# RS1xxxx register map
Vendor: Silicon Lab Inc.; Series: ARMCM4; File version: 1.2
CPU: CM4 r1p0, little endian, MPU, FPU, 6 interrupt priority bits
Registers are 32-bit, read-write, reset 0x0 unless marked. A register's access mark holds for its fields unless they carry their own. Offsets are from the block's base; [hi:lo] are bit positions; lines under a group give offsets from that group; {n}, {i} and the like mark numbered series; 'fields as' and 'values as' point back to an identical list.

## AUX_ADC_DAC_COMP — The ADC-DAC Controller works on a ADC with a resolution of 12bits at 5Mega sample per second when ADC reference Voltage is greater than 2.8v or 5Mega sample per second when ADC reference Voltage is less than 2.8v.
Base 0x24043800
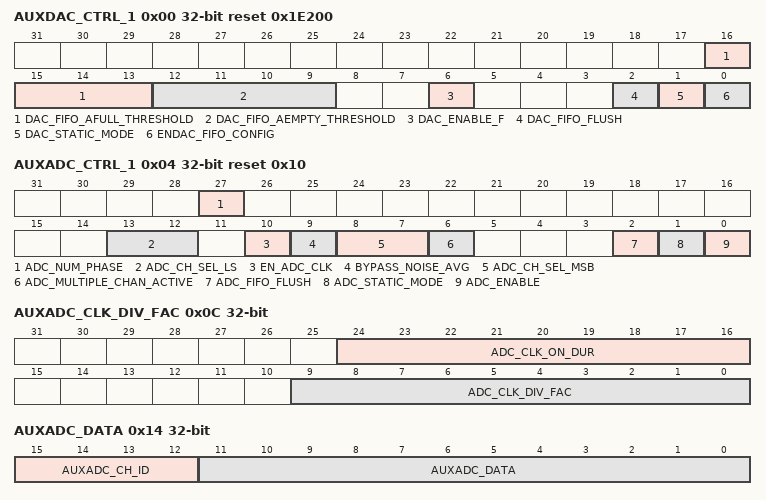
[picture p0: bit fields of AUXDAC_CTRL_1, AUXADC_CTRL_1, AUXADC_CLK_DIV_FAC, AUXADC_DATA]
0x00 AUXDAC_CTRL_1 reset 0x1E200 — Control register1 for DAC
  [16:13] DAC_FIFO_AFULL_THRESHOLD — It is recommended to write these bits to 0
  [12:9] DAC_FIFO_AEMPTY_THRESHOLD — It is recommended to write these bits to 0
  [6] DAC_ENABLE_F — This bit is used to enable AUX DAC controller ,valid only when DAC enable is happpen
    1=Enable DAC Controller; 0=Disable DAC Controller
  [2] DAC_FIFO_FLUSH — This bit is used to flush the DAC FIFO.
    1=Enable (Flush dac FIFO); 0=Disable (Do not flush)
  [1] DAC_STATIC_MODE — This bit is used to select non-FIFO mode in DAC.
    1=Enable (Static mode is enabled. Data written to the DAC_DATA_REG will not be written to the FIFO. It will be played on DAC directly. Only single sample can be held at a time); 0=Disable (FIFO mode enabled. Data written to the DAC_DATA_REG is written to the FIFO in this mode. In either of these modes, data will be driven to the DAC only when dac_enable is set.)
  [0] ENDAC_FIFO_CONFIG — This bit activates the DAC path in Aux ADC-DAC controller. Data samples will be played on DAC only when this bit is set.
    1=Enable fifo configuration of DAC; 0=Disable fifo configuration of DAC
0x04 AUXADC_CTRL_1 reset 0x10 — Control register1 for ADC
  [27] ADC_NUM_PHASE — ADC number of phase
  [13:12] ADC_CH_SEL_LS — Aux ADC channel number from which the data has to be sampled This is valid only when adc multiple channel active is zero. When channel number is greater than three, upper bits should also be programmed ADC CHANNEL SELECT MS to bits in this register
    {v}=CHANNEL_{v} (v=0..3)
  [10] EN_ADC_CLK — Enable AUX ADC Divider output clock
  [9] BYPASS_NOISE_AVG — ADC in Bypass noise avg mode.
  [8:7] ADC_CH_SEL_MSB — Upper 2-bits of adc channel select.When the channel number is greater than 3, these have to be used.It is recommended to write these bits to 0
  [6] ADC_MULTIPLE_CHAN_ACTIVE — This bit is used to control the auxadc sel signal going to the Aux ADC.
    1=Enable (Data will be sampled from four ADC channels in sequential order and written to the receive FIFO in the same order.); 0=Disable (Data will be sampled from the programmed ADC channel)
  [2] ADC_FIFO_FLUSH — This bit is used to flush the ADC FIFO
    1=Enable (Flush ADC FIFO); 0=Disable (Do not flush)
  [1] ADC_STATIC_MODE — This bit is used to select non-FIFO mode in ADC.
    1=Enable (Static mode enable here data directly to register not in FIFO); 0=Disable (FIFO mode enabled here data directly to FIFO.)
  [0] ADC_ENABLE — This bits activates the ADC path in Aux ADC-DAC controller.
    1=Enable ADC; 0=Disable ADC
0x08 AUXDAC_CLK_DIV_FAC — DAC clock division register
  [9:0] DAC_CLK_DIV_FAC — These bits control the DAC clock division factor
0x0C AUXADC_CLK_DIV_FAC — ADC clock division register
  [24:16] ADC_CLK_ON_DUR — These bits control the On-Duration of the ADC clock
  [9:0] ADC_CLK_DIV_FAC — These bits control the Total-Duration of the ADC clock
0x10 AUXDAC_DATA — Writing to this register will fill DAC FIFO for streaming Data to DAC
  [9:0] AUXDAC_DATA
0x14 AUXADC_DATA — AUXADC Data Read through Register.
  [15:12] AUXADC_CH_ID ro — AUXADC Channel ID
  [11:0] AUXADC_DATA ro — AUXADC Data Read through Register
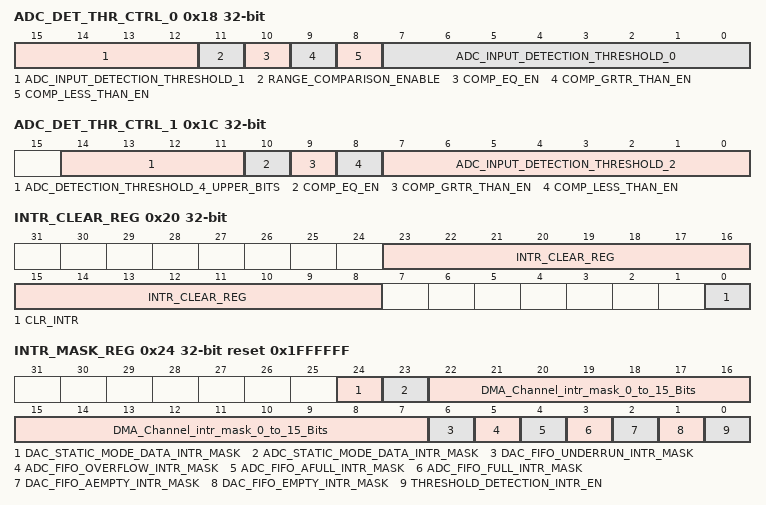
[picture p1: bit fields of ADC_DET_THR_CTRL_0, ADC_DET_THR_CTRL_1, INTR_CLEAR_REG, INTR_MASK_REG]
0x18 ADC_DET_THR_CTRL_0 — ADC detection threshold control 0
  [15:12] ADC_INPUT_DETECTION_THRESHOLD_1 — Carries upper four bits of ADC detection threshold
  [11] RANGE_COMPARISON_ENABLE — When set, Aux ADC-DAC controller raises an interrupt to processor when the Aux ADC output falls within the range specified in AUX ADC Detection threshold0 and AUX ADC Detection threshold1
    1=Enable range comparison; 0=Disable range comparison
  [10] COMP_EQ_EN — When set, Aux ADC-DAC controller raises an interrupt to processor when the Aux ADC output is equal to the programmed Aux ADC detection threshold
    1=Enable compare equal bit; 0=Disable compare equal bit
  [9] COMP_GRTR_THAN_EN — When set, Aux ADC-DAC controller raises an interrupt to processor when the Aux ADC output is greater than the programmed Aux ADC detection threshold..
    1=Enable grater than mode; 0=Disable grater than mode
  [8] COMP_LESS_THAN_EN — When set, Aux ADC-DAC controller raises an interrupt to processor when the Aux ADC output falls below the programmed Aux ADC detection threshold.
    1=Enable less than mode; 0=Disable less than mode
  [7:0] ADC_INPUT_DETECTION_THRESHOLD_0 — The value against which the ADC output has to be compared is to be programmed in this register
0x1C ADC_DET_THR_CTRL_1 — ADC detection threshold control 1
  [14:11] ADC_DETECTION_THRESHOLD_4_UPPER_BITS — Upper 4 bits of ADC detection threshold 2 for ADC
  [10] COMP_EQ_EN — When set, Aux ADC-DAC controller raises an interrupt to TA when the Aux ADC output is equal to the programmed Aux ADC detection threshold.
    1=Enable compare equal bit; 0=Disable compare equal bit
  [9] COMP_GRTR_THAN_EN — When set, Aux ADC-DAC controller raises an interrupt to TA when the Aux ADC output is greater than the programmed Aux ADC detection threshold.
    1=Enable grater than mode; 0=Disable grater than mode
  [8] COMP_LESS_THAN_EN — When set, Aux ADC-DAC controller raises an interrupt to TA when the Aux ADC output falls below the programmed Aux ADC detection threshold.
    1=Enable less than mode; 0=Disable less than mode
  [7:0] ADC_INPUT_DETECTION_THRESHOLD_2 — The value against which the ADC output has to be compared is to be programmed in this register.
0x20 INTR_CLEAR_REG — ADC detection threshold control 1
  [23:8] INTR_CLEAR_REG — If enabled, corresponding first_mem_switch_intr bits will be cleared.
  [0] CLR_INTR — This bit is used to clear threshold detection interrupt
    1=CLEAR_INTERRUPT (Clear the interrupt); 0=NO_EFFECT (Disable compare equal bit)
0x24 INTR_MASK_REG reset 0x1FFFFFF — Mask interrupt register
  [24] DAC_STATIC_MODE_DATA_INTR_MASK — When Cleared, dac static_mode_data_intr will be unmasked
  [23] ADC_STATIC_MODE_DATA_INTR_MASK — When Cleared, adc static_mode_data_intr will be unmasked
  [22:7] DMA_Channel_intr_mask_0_to_15_Bits — When Cleared, first_mem_switch_intr will be unmasked
  [6] DAC_FIFO_UNDERRUN_INTR_MASK — When Cleared, dac FIFO underrun interrupt will be unmasked
    1=MASK_INTERRUPT (When bit is set mask the interrupt); 0=UNMASK_EFFECT (When bit is clear unmask the interrupt)
  [5] ADC_FIFO_OVERFLOW_INTR_MASK — When Cleared, dac FIFO underrun interrupt will be unmasked
    values as DAC_FIFO_UNDERRUN_INTR_MASK
  [4] ADC_FIFO_AFULL_INTR_MASK — When Cleared, adc FIFO afull interrupt will be unmasked
    values as DAC_FIFO_UNDERRUN_INTR_MASK
  [3] ADC_FIFO_FULL_INTR_MASK — When Cleared, adc FIFO full interrupt will be unmasked
    values as DAC_FIFO_UNDERRUN_INTR_MASK
  [2] DAC_FIFO_AEMPTY_INTR_MASK — When Cleared, adc FIFO full interrupt will be unmasked
    values as DAC_FIFO_UNDERRUN_INTR_MASK
  [1] DAC_FIFO_EMPTY_INTR_MASK — When Cleared, dac_FIFO_empty interrupt will be unmasked
    values as DAC_FIFO_UNDERRUN_INTR_MASK
  [0] THRESHOLD_DETECTION_INTR_EN — When Cleared, threshold detection interrupt will be unmasked
    values as DAC_FIFO_UNDERRUN_INTR_MASK
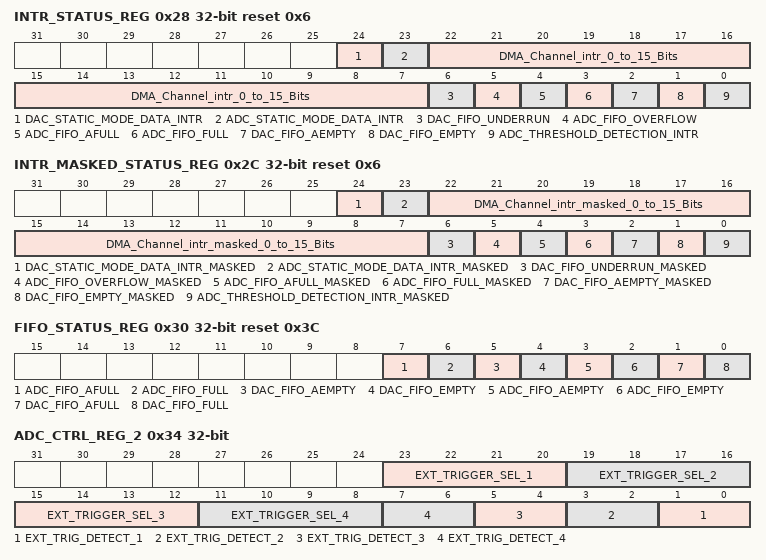
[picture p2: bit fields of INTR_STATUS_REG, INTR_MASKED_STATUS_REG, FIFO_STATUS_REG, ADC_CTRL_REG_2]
0x28 INTR_STATUS_REG ro reset 0x6 — Status interrupt register
  [24] DAC_STATIC_MODE_DATA_INTR — Set when a proper data packet is ready to read in static mode for DAC
  [23] ADC_STATIC_MODE_DATA_INTR — Set when a proper data packet is ready to read in static mode for ADC
  [22:7] DMA_Channel_intr_0_to_15_Bits — Interrupt indicating the first memory has been filled and the DMA write is being shifted to second memory chunk for ping-pong operation
  [6] DAC_FIFO_UNDERRUN — Set when a read is done on DAC FIFO when the FIFO is empty
  [5] ADC_FIFO_OVERFLOW — Set when a write attempt is made to ADC FIFO when the FIFO is already full
  [4] ADC_FIFO_AFULL — Set when ADC FIFO occupancy less than or equal to ADC FIFO threshold
  [3] ADC_FIFO_FULL — Set when ADC FIFO is full,This bit gets cleared when data is read from the FIFO
  [2] DAC_FIFO_AEMPTY — Set when the FIFO occupancy grater than or equal to DAC FIFO threshold.
  [1] DAC_FIFO_EMPTY — Set when DAC FIFO is empty. This bit gets cleared when the DAC FIFO at least a single sample is available in DAC FIFO
  [0] ADC_THRESHOLD_DETECTION_INTR — This bit is set when ADC threshold matches with the programmed conditions This will be be cleared as soon as this interrupt is acknowledged by processor
0x2C INTR_MASKED_STATUS_REG ro reset 0x6 — Interrupt masked status register
  [24] DAC_STATIC_MODE_DATA_INTR_MASKED — Masked Interrupt. Set when a proper data packet is ready to read in static mode for DAC
  [23] ADC_STATIC_MODE_DATA_INTR_MASKED — Masked Interrupt. Set when a proper data packet is ready to read in static mode for ADC
  [22:7] DMA_Channel_intr_masked_0_to_15_Bits — Masked Interrupt status indicating the first memory has been filled and the DMA write is being shifted to second memory chunk for ping-pong operation
  [6] DAC_FIFO_UNDERRUN_MASKED — Masked Interrupt. Set when a read is done on DAC FIFO when the FIFO is empty.
  [5] ADC_FIFO_OVERFLOW_MASKED — Masked Interrupt. Set when a write attempt is made to ADC FIFO when the FIFO is already full.
  [4] ADC_FIFO_AFULL_MASKED — Masked Interrupt. Set when ADC FIFO occupancy greater than ADC FIFO threshold
  [3] ADC_FIFO_FULL_MASKED — Masked Interrupt. Set when ADC FIFO is full.
  [2] DAC_FIFO_AEMPTY_MASKED — Masked Interrupt. Set when the FIFO occupancy less than equal to DAC FIFO threshold.
  [1] DAC_FIFO_EMPTY_MASKED — Masked Interrupt.Set when DAC FIFO is empty
  [0] ADC_THRESHOLD_DETECTION_INTR_MASKED — Masked Interrupt. This bit is set when ADC threshold matches with the programmed conditions
0x30 FIFO_STATUS_REG ro reset 0x3C — Interrupt masked status register
  [7] ADC_FIFO_AFULL — Set when ADC FIFO occupancy greater than ADC FIFO threshold.
  [6] ADC_FIFO_FULL — Set when ADC FIFO is full. This bit gets cleared when data is read from the FIFO.
  [5] DAC_FIFO_AEMPTY — Set when the FIFO occupancy less than DAC FIFO threshold
  [4] DAC_FIFO_EMPTY — Set when FIFO is empty. This bit gets cleared when the DAC FIFO is not empty.
  [3] ADC_FIFO_AEMPTY — Set when the FIFO occupancy less than ADC FIFO threshold
  [2] ADC_FIFO_EMPTY — Set when FIFO is empty. This bit gets cleared when the ADC FIFO is not empty.
  [1] DAC_FIFO_AFULL — Set when DAC FIFO occupancy greater than FIFO threshold
  [0] DAC_FIFO_FULL — Set when DAC FIFO is full. In word mode, FIFO will be shown as full unless there is space for 16-bits.
0x34 ADC_CTRL_REG_2 — ADC Control register2
  [23:20] EXT_TRIGGER_SEL_1 — 4-bit Channel ID corresponding to external trigger 1.
  [19:16] EXT_TRIGGER_SEL_2 — Enable bit corresponding to channel id selected for trigger 2.
  [15:12] EXT_TRIGGER_SEL_3 — 4-bit Channel ID corresponding to external trigger 3.
  [11:8] EXT_TRIGGER_SEL_4 — 4-bit Channel ID corresponding to external trigger 4.
  [2n-1:2n-2] EXT_TRIG_DETECT_{n} (n=1..4) — Condition to detect event on external trigger {n} 00: None (trigger disabled) 01: Positive edge 10: Negative edge 11: Positive or negative edge.
{0x38+0x10*i} ADC_CHn_BIT_MAP_CONFIG[{i}] (i=0..15) group — ADC Channel bit map configuration registers(0-15)
  {0x0+4j} ADC_CH_n__BIT_MAP_CONFIG_{j} (j=0..2) — This is configuration register{j} to explain the bit map for ADC channels
    [31:0] CHANNEL__n__BITMAP — ADC Channels bit map
  0x0C ADC_CH_n__BIT_MAP_CONFIG_3 — This is configuration register3 to explain the bit map for ADC channels
    [4:0] CHANNEL__n__BITMAP — ADC Channels bit map
{0x138+4i} ADC_CHn_OFFSET[{i}] (i=0..15) group — Initial offset value with respect to AUX_ADC clock after which Channel(0-15)should be sampled
  0x00 ADC_CH_n1__OFFSET — This Register specifies initial offset value with respect to AUX_ADC clock after which should sample channel.
    [15:0] CH_n__OFFSET — This Register field specifies initial offset value with respect to AUX_ADC clock after which Channel(0-16)should be sampled.
{0x178+4i} ADC_CHn_FREQ[{i}] (i=0..15) group — This register specifies Sampling frequency rate at which AUX ADC Date is sampled for Channel(1 to 16 )
  0x00 ADC_CH_n1__FREQ — This register specifies Sampling frequency rate at which AUX ADC Date is sampled for Channel
    [15:0] CH_n__FREQ_VALUE — This register specifies Sampling frequency rate at which AUX ADC Date is sampled for Channel all respective channel (1-16)
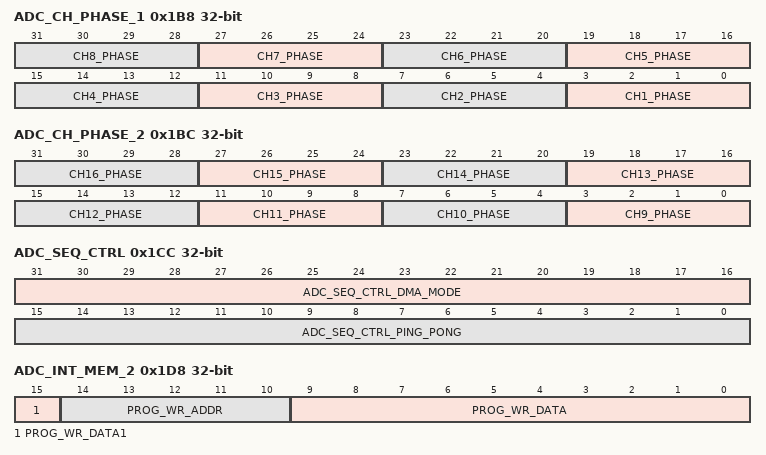
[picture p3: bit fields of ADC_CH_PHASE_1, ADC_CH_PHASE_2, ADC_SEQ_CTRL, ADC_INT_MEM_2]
0x1B8 ADC_CH_PHASE_1 — ADC Channel Phase 1
  [4n-1:4n-4] CH{n}_PHASE (n=1..8) — Phase corresponding to channel-{n}
0x1BC ADC_CH_PHASE_2 — ADC Channel Phase 2
  [4n-33:4n-36] CH{n}_PHASE (n=9..16) — Phase corresponding to channel-{n}
0x1C4 ADC_SINGLE_CH_CTRL_1 — ADC SINGLE Channel Configuration
  [31:0] ADC_CH_INDEX_SINGLE_CHAN_1 — [31:0]out of total 48 bits of bit map for single channel mode of a particular channel.
0x1C8 ADC_SINGLE_CH_CTRL_2 — ADC SINGLE Channel Configuration
  [15:0] ADC_CH_INDEX_SINGLE_CHAN_2 — [47:32] out of total 48 bits of bit map for single channel mode of a particular channel.
0x1CC ADC_SEQ_CTRL — This register explain configuration parameter for AUXADC
  [31:16] ADC_SEQ_CTRL_DMA_MODE — To enable/disable per channel ping-pong operation (One-hot coding).
  [15:0] ADC_SEQ_CTRL_PING_PONG — To enable/disable per channel DAM mode (One-hot coding)
0x1D0 VAD_BBP_ID — This register explain VDD BBP ID
  [31:16] DISCONNET_MODE — Per channel discontinuous mode enable signal. When discontinuous mode is enabled,data is sampled only once from that channel and the enable bit is reset to 0.
0x1D4 ADC_INT_MEM_1 — This register explain start address of first/second buffer corresponding to the channel location ADC INT MEM 2
  [31:0] PROG_WR_DATA — These 32-bits specifies the start address of first/second buffer corresponding to the channel location ADC INT MEM
0x1D8 ADC_INT_MEM_2 — This register explain ADC INT MEM2.
  [15] PROG_WR_DATA1 — Valid bit for first/second buffers corresponding to ADC INT MEM2
  [14:10] PROG_WR_ADDR — These bits correspond to the address of the internal memory basing on the channel number, whose information we want to program
  [9:0] PROG_WR_DATA — These 10-bits specify the buffer length of first/second buffer corresponding to the channel location ADC INT MEM2
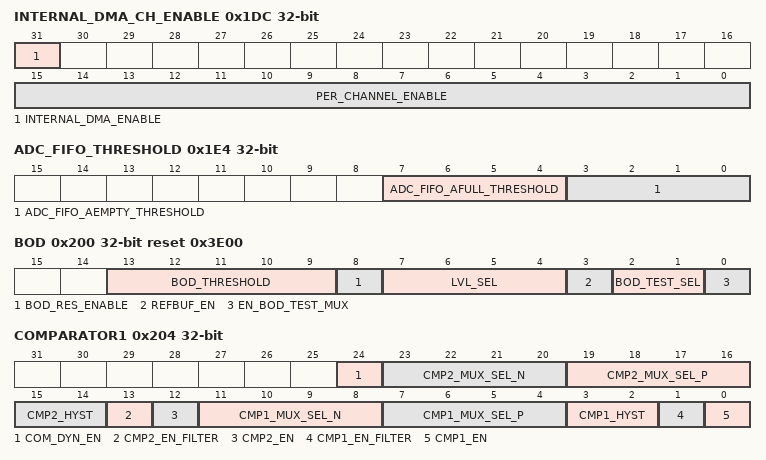
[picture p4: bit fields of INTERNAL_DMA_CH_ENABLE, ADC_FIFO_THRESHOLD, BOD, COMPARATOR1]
0x1DC INTERNAL_DMA_CH_ENABLE — This register is internal channel enable
  [31] INTERNAL_DMA_ENABLE — When Set, Internal DMA will be used for reading ADC samples from ADC FIFO and writing them to ULP SRAM Memories.
  [15:0] PER_CHANNEL_ENABLE — Enable bit for Each channel,like channel0 for bit0 to channel15 for bit15 etc
0x1E0 TS_PTAT_ENABLE — This register is enable PTAT for temperature sensor
  [0] TS_PTAT_EN — BJT based Temperature sensor
    1=Enable PTAT bit; 0=Disable PTAT bit
0x1E4 ADC_FIFO_THRESHOLD wo — Configured FIFO to ADC
  [7:4] ADC_FIFO_AFULL_THRESHOLD — FIFO almost full threshold for ADC
  [3:0] ADC_FIFO_AEMPTY_THRESHOLD — FIFO almost empty threshold for ADC
0x200 BOD reset 0x3E00 — Programs resistor bank, reference buffer and scaler
  [13:9] BOD_THRESHOLD — Programmability for resistor bank
  [8] BOD_RES_ENABLE — configuration of register bank 1 for enable and 0 for disable
    0=Disable register bank bit; 1=Enable register bank bit
  [7:4] LVL_SEL — selection of voltage of reference buffer
  [3] REFBUF_EN — Reference buffer configuration 1 for enable 0 for disable
    0=Disable reference buffer enable bit; 1=Enable reference buffer enable bit
  [2:1] BOD_TEST_SEL — Select bits for test mux
  [0] EN_BOD_TEST_MUX — 1 - To enable test mux
0x204 COMPARATOR1 — Programs comparators1 and comparators2
  [24] COM_DYN_EN — Dynamic enable for registers
  [23:20] CMP2_MUX_SEL_N — Select for negative input of comparator_2
    0=comp2_n0 (external pin as negative input for comparator2); 1=comp2_n1 (external pin as negative input for comparator2); 2=DAC (DAC as negative input for comparator2); 3=reference_buffer_out as negative input for comparator2; 4=reference_scaler_out as negative input for comparator2; 5=register_bank_out as negative input for comparator2; 6=opamp1 as negative input for comparator2; 7=opamp2 as negative input for comparator2; 8=opamp3 as negative input for comparator2
  [19:16] CMP2_MUX_SEL_P — Select for positive input of comparator_2
    0=comp2_p0 (external pin as positive input for comparator2); 1=comp2_p1 (external pin as positive input for comparator2); 2=DAC (DAC as positive input for comparator2); 3=reference_buffer_out as positive input for comparator2; 4=reference_scaler_out as positive input for comparator2; 5=register_bank_out as positive input for comparator2; 6=opamp1 as positive input for comparator2; 7=opamp2 as positive input for comparator2; 8=opamp3 as positive input for comparator2
  [15:14] CMP2_HYST — Programmability to control hysteresis of comparator2
  [13] CMP2_EN_FILTER — To enable filter for comparator 2
    0=Disable filter for comparator2; 1=Enable filter to comparator2
  [12] CMP2_EN — To enable comparator 2
    0=Disable comparator2; 1=Enable comparator2
  [11:8] CMP1_MUX_SEL_N — Select for negative input of comparator_1
    0=comp1_n0 (external pin as negative input for comparator1); 1=comp1_n1 (external pin as negative input for comparator1); 2=DAC (DAC as negative input for comparator1); 3=reference_buffer_out as negative input for comparator1; 4=reference_scaler_out as negative input for comparator1; 5=register_bank_out as negative input for comparator1; 6=opamp1 as negative input for comparator1; 7=opamp2 as negative input for comparator1; 8=opamp3 as negative input for comparator1
  [7:4] CMP1_MUX_SEL_P — Select for positive input of comparator_1
    0=comp1_p0 (external pin as positive input for comparator1); 1=comp1_p1 (external pin as positive input for comparator1); 2=DAC (DAC as positive input for comparator1); 3=reference_buffer_out as positive input for comparator1; 4=reference_scaler_out as positive input for comparator1; 5=register_bank_out as positive input for comparator1; 6=opamp1 as positive input for comparator1; 7=opamp2 as positive input for comparator1; 8=opamp3 as positive input for comparator1
  [3:2] CMP1_HYST — Programmability to control hysteresis of comparator1
  [1] CMP1_EN_FILTER — To enable filter for comparator 1
    0=Disable filter for comparator1; 1=Enable filter to comparator1
  [0] CMP1_EN — To enable comparator1
    0=Disable comparator1; 1=Enable comparator1
0x208 AUXADC_CONFIG_2 — This register is AUX-ADC config2
  [11] AUXADC_DYN_ENABLE — Aux ADC Configuration Enable
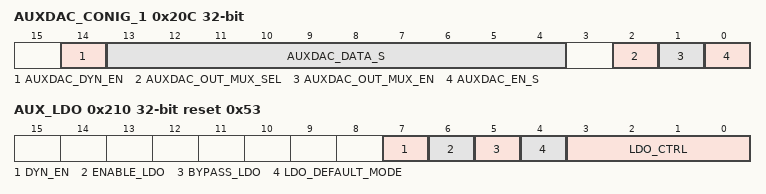
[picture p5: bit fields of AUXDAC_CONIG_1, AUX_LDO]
0x20C AUXDAC_CONIG_1 — This register is AUX-DAC config1
  [14] AUXDAC_DYN_EN — Satatic AUX Dac Data
  [13:4] AUXDAC_DATA_S — Satatic AUX Dac Data
  [2] AUXDAC_OUT_MUX_SEL — AUXDAC OUT MUX SELECT Enable
    1=Enable (DAC Output is connected to AGPIO15); 0=Disable (DAC Output is connected to AGPIO4)
  [1] AUXDAC_OUT_MUX_EN — Aux OUT mux Enable
    1=Enable (DAC output is connected to PAD); 0=Disable (DAC output is not connected to PAD)
  [0] AUXDAC_EN_S — Enable signal DAC
0x210 AUX_LDO reset 0x53 — This register is AUX-LDO configuration
  [7] DYN_EN — Dynamic Enable
  [6] ENABLE_LDO — Turn LDO
  [5] BYPASS_LDO — bypass the LDO
  [4] LDO_DEFAULT_MODE — ldo default mode enable
  [3:0] LDO_CTRL — Enable ldo control field
